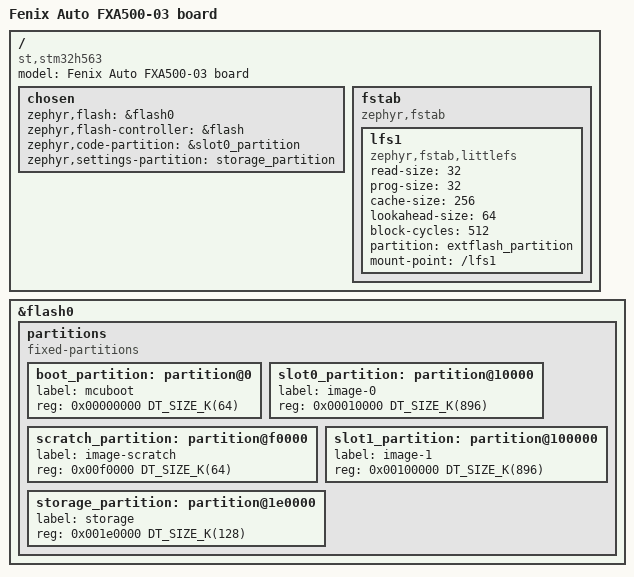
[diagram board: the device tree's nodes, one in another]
/dts-v1/;
#include "fxa500_03-common.dtsi"
#include "fxa500_03-flash-memmapped.dtsi"
// #include "fxa500_03-flash-as-spi.dtsi"


/ {
	model = "Fenix Auto FXA500-03 board";
	compatible = "st,stm32h563";

	chosen {
		zephyr,flash = &flash0;
		zephyr,flash-controller = &flash;
		zephyr,code-partition = &slot0_partition;
		zephyr,settings-partition = <&storage_partition>;
	};

	fstab {
		compatible = "zephyr,fstab";
		lfs1: lfs1 {
			compatible = "zephyr,fstab,littlefs";
			read-size = <32>;
			prog-size = <32>;
			cache-size = <256>;
			lookahead-size = <64>;
			block-cycles = <512>;
			partition = <&extflash_partition>;
			mount-point = "/lfs1";
		};
	};
};

&flash0 {
	partitions {
		compatible = "fixed-partitions";
		#address-cells = <1>;
		#size-cells = <1>;

		boot_partition: partition@0 {
			label = "mcuboot";
			reg = <0x00000000 DT_SIZE_K(64)>;
		};

		slot0_partition: partition@10000 {
			label = "image-0";
			reg = <0x00010000 DT_SIZE_K(896)>;
			// Можливий варіант розміщення slot1 у зовнішньому Flash
			// Але зараз краще не робити, бо є нюанси
			// Один з них, це верогідність шо прошивка буде
			// сама перезаписуватись, і не допоможе нічого, навіть
			// стрирання Flash процесора
            // reg = <0x00010000 DT_SIZE_K(1920)>;
		};

		scratch_partition: partition@f0000 {
			label = "image-scratch";
			reg = <0x00f0000 DT_SIZE_K(64)>;
		};

		slot1_partition: partition@100000 {
			label = "image-1";
			reg = <0x00100000 DT_SIZE_K(896)>;
		};

		storage_partition: partition@1e0000 {
			label = "storage";
			reg = <0x001e0000 DT_SIZE_K(128)>;
		};
	};
};

// &w25q128jv {
// // &ext_flash {
// 	partitions {
// 		compatible = "fixed-partitions";
// 		#address-cells = <1>;
// 		#size-cells = <1>;

//         storage_partition: partition@0 {
// 			label = "storage";
// 			reg = <0x00000000 DT_SIZE_M(16)>;
// 		};

// 		// partition@0 {
// 		// 	label = "nor";
// 		// 	reg = <0x00000000 DT_SIZE_M(16)>;
// 		// };
// 	};
// };
